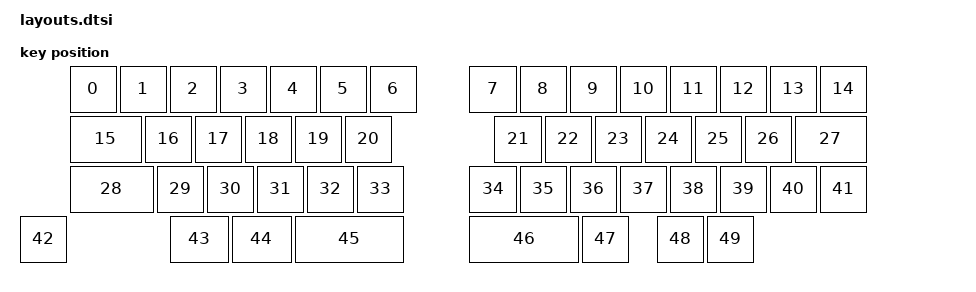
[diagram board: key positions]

#include <physical_layouts.dtsi>
/ {
    physical_layout0: physical_layout0 {
        compatible = "zmk,physical-layout";
        display-name = "Layout";
        keys
            = <&key_physical_attrs 100 100 50 0 0 0 0>
			,<&key_physical_attrs 100 100 150 0 0 0 0>
			,<&key_physical_attrs 100 100 250 0 0 0 0>
			,<&key_physical_attrs 100 100 350 0 0 0 0>
			,<&key_physical_attrs 100 100 450 0 0 0 0>
			,<&key_physical_attrs 100 100 550 0 0 0 0>
			,<&key_physical_attrs 100 100 650 0 0 0 0>
			,<&key_physical_attrs 100 100 850 0 0 0 0>
			,<&key_physical_attrs 100 100 950 0 0 0 0>
			,<&key_physical_attrs 100 100 1050 0 0 0 0>
			,<&key_physical_attrs 100 100 1150 0 0 0 0>
			,<&key_physical_attrs 100 100 1250 0 0 0 0>
			,<&key_physical_attrs 100 100 1350 0 0 0 0>
			,<&key_physical_attrs 100 100 1450 0 0 0 0>
			,<&key_physical_attrs 100 100 1550 0 0 0 0>
			,<&key_physical_attrs 150 100 50 100 0 0 0>
			,<&key_physical_attrs 100 100 200 100 0 0 0>
			,<&key_physical_attrs 100 100 300 100 0 0 0>
			,<&key_physical_attrs 100 100 400 100 0 0 0>
			,<&key_physical_attrs 100 100 500 100 0 0 0>
			,<&key_physical_attrs 100 100 600 100 0 0 0>
			,<&key_physical_attrs 100 100 900 100 0 0 0>
			,<&key_physical_attrs 100 100 1000 100 0 0 0>
			,<&key_physical_attrs 100 100 1100 100 0 0 0>
			,<&key_physical_attrs 100 100 1200 100 0 0 0>
			,<&key_physical_attrs 100 100 1300 100 0 0 0>
			,<&key_physical_attrs 100 100 1400 100 0 0 0>
			,<&key_physical_attrs 150 100 1500 100 0 0 0>
			,<&key_physical_attrs 175 100 50 200 0 0 0>
			,<&key_physical_attrs 100 100 225 200 0 0 0>
			,<&key_physical_attrs 100 100 325 200 0 0 0>
			,<&key_physical_attrs 100 100 425 200 0 0 0>
			,<&key_physical_attrs 100 100 525 200 0 0 0>
			,<&key_physical_attrs 100 100 625 200 0 0 0>
			,<&key_physical_attrs 100 100 850 200 0 0 0>
			,<&key_physical_attrs 100 100 950 200 0 0 0>
			,<&key_physical_attrs 100 100 1050 200 0 0 0>
			,<&key_physical_attrs 100 100 1150 200 0 0 0>
			,<&key_physical_attrs 100 100 1250 200 0 0 0>
			,<&key_physical_attrs 100 100 1350 200 0 0 0>
			,<&key_physical_attrs 100 100 1450 200 0 0 0>
			,<&key_physical_attrs 100 100 1550 200 0 0 0>
			,<&key_physical_attrs 100 100 (-50) 300 0 0 0>
			,<&key_physical_attrs 125 100 250 300 0 0 0>
			,<&key_physical_attrs 125 100 375 300 0 0 0>
			,<&key_physical_attrs 225 100 500 300 0 0 0>
			,<&key_physical_attrs 225 100 850 300 0 0 0>
			,<&key_physical_attrs 100 100 1075 300 0 0 0>
			,<&key_physical_attrs 100 100 1225 300 0 0 0>
			,<&key_physical_attrs 100 100 1325 300 0 0 0>
            ;
    };
};
    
